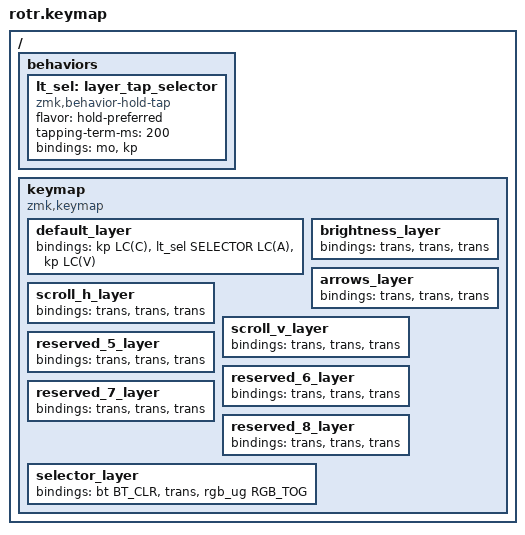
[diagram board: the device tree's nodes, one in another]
/*
 * Copyright (c) 2026 Carl Henriksson
 * SPDX-License-Identifier: MIT
 *
 * ROTR "Path C" Stage 3 keymap.
 *
 * Key positions (1 row x 3 cols), physical mapping confirmed on hardware:
 *   position 0 = LEFT   = Copy       &kp LC(C)
 *   position 1 = MIDDLE = Select-All / hold = selector
 *   position 2 = RIGHT  = Paste      &kp LC(V)
 *
 * MIDDLE is a hold-tap (&lt_sel): TAP = Select-All LC(A); HOLD = momentary
 * selector layer. While the selector layer is held the knob is in "select"
 * mode (driver layer-modes table) and turning cycles the active base layer
 * (0-4); releasing lands on it. This reimplements the stock ROTR selector.
 *
 * The three buttons stay Copy / Select-All / Paste on every active layer:
 * layers 1-8 leave them &trans so they fall through to the default layer.
 *
 * The knob behaviour per layer is decided in the MA730 driver's DT mode
 * table (boards/polarityworks/rotr/rotr_nrf52840_zmk.dts: layer-modes).
 *
 * Layers: 0 default, 1 brightness, 2 arrows, 3 scroll-h, 4 scroll-v,
 *         5-8 reserved (inactive scaffolds, excluded from the selector
 *         until select-layer-count is raised), 9 selector.
 */

#include <behaviors.dtsi>
#include <dt-bindings/zmk/keys.h>
#include <dt-bindings/zmk/bt.h>
#include <dt-bindings/zmk/rgb.h>
#include "rotr-ma730.h"

#define SELECTOR ROTR_SELECT_LAYER

/ {
	behaviors {
		/*
		 * Middle button: tap = Select-All, hold = momentary selector.
		 * hold-preferred so holding-then-turning (and hold+tap-right for
		 * the RGB toggle) engages the selector reliably; a quick tap
		 * still yields Select-All. tapping-term-ms is the feel tweak.
		 */
		lt_sel: layer_tap_selector {
			compatible = "zmk,behavior-hold-tap";
			#binding-cells = <2>;
			flavor = "hold-preferred";
			tapping-term-ms = <200>;
			bindings = <&mo>, <&kp>;
		};
	};

	keymap {
		compatible = "zmk,keymap";

		/* 0: default — knob inactive. */
		default_layer {
			bindings = <
				&kp LC(C)
				&lt_sel SELECTOR LC(A)
				&kp LC(V)
			>;
		};

		/* 1: brightness — F13 (CW) / F14 (CCW). */
		brightness_layer {
			bindings = <&trans &trans &trans>;
		};

		/* 2: arrows — Right (CW) / Left (CCW). */
		arrows_layer {
			bindings = <&trans &trans &trans>;
		};

		/* 3: scroll-h — smooth horizontal wheel. */
		scroll_h_layer {
			bindings = <&trans &trans &trans>;
		};

		/* 4: scroll-v — smooth vertical wheel (CW = down). */
		scroll_v_layer {
			bindings = <&trans &trans &trans>;
		};

		/* 5: reserved — pre-loaded volume (inactive until count raised). */
		reserved_5_layer {
			bindings = <&trans &trans &trans>;
		};

		/* 6: reserved scaffold. */
		reserved_6_layer {
			bindings = <&trans &trans &trans>;
		};

		/* 7: reserved scaffold. */
		reserved_7_layer {
			bindings = <&trans &trans &trans>;
		};

		/* 8: reserved scaffold. */
		reserved_8_layer {
			bindings = <&trans &trans &trans>;
		};

		/*
		 * 9: selector (held). LEFT = clear BT bonds, MIDDLE = trans (the
		 * hold itself), RIGHT = toggle underglow (HOLD MIDDLE + TAP RIGHT).
		 */
		selector_layer {
			bindings = <
				&bt BT_CLR
				&trans
				&rgb_ug RGB_TOG
			>;
		};
	};
};
